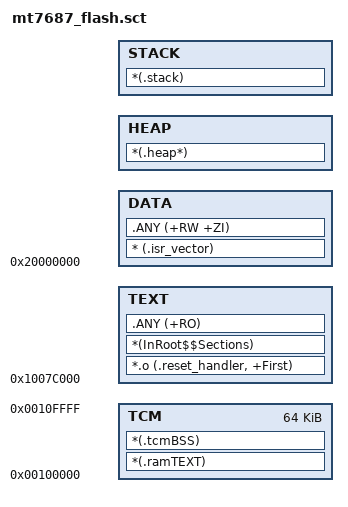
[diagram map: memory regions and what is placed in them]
#! armcc -E

;******************************************************************************************
;ROM_CODE definition: 
;    - ROM_CODE_BASE: 
;    - ROM_CODE_SIZE:  20K
;******************************************************************************************
#define ROM_CODE_BASE 0x0
#define ROM_CODE_SIZE 0x00005000

;******************************************************************************************
;TCMRAM definition: 
;    - TCMRAM_BASE: 
;    - TCMRAM_SIZE:  64K
;******************************************************************************************
#define TCMRAM_BASE 0x00100000
#define TCMRAM_SIZE 0x00010000

;******************************************************************************************
;XIP_CODE definition: 
;    - XIP_CODE_BASE: 
;    - XIP_CODE_SIZE:  764K
;******************************************************************************************
#define XIP_CODE_BASE 0x1007C000
#define XIP_CODE_SIZE 0x000BF000

;******************************************************************************************
;SYSRAM definition: 
;    - SYSRAM_BASE: 
;    - SYSRAM_SIZE:  256K
;******************************************************************************************
#define SYSRAM_BASE 0x20000000
#define SYSRAM_SIZE 0x00040000


XIP XIP_CODE_BASE XIP_CODE_SIZE
{
    TEXT XIP_CODE_BASE
    { 
     *.o (.reset_handler, +First)
     *(InRoot$$Sections)
     .ANY (+RO)
    }
    DATA SYSRAM_BASE
    { 
     * (.isr_vector)
    .ANY (+RW +ZI)
    }
    HEAP +0x0
    {
        *(.heap*)
    }
    STACK +0x0
    {
        *(.stack)
    }
    ScatterAssert(ImageLimit(STACK)  < (SYSRAM_BASE + SYSRAM_SIZE))
    
    TCM TCMRAM_BASE TCMRAM_SIZE
    { 
        *(.ramTEXT)
        *(.tcmBSS)
    }

    
    
}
